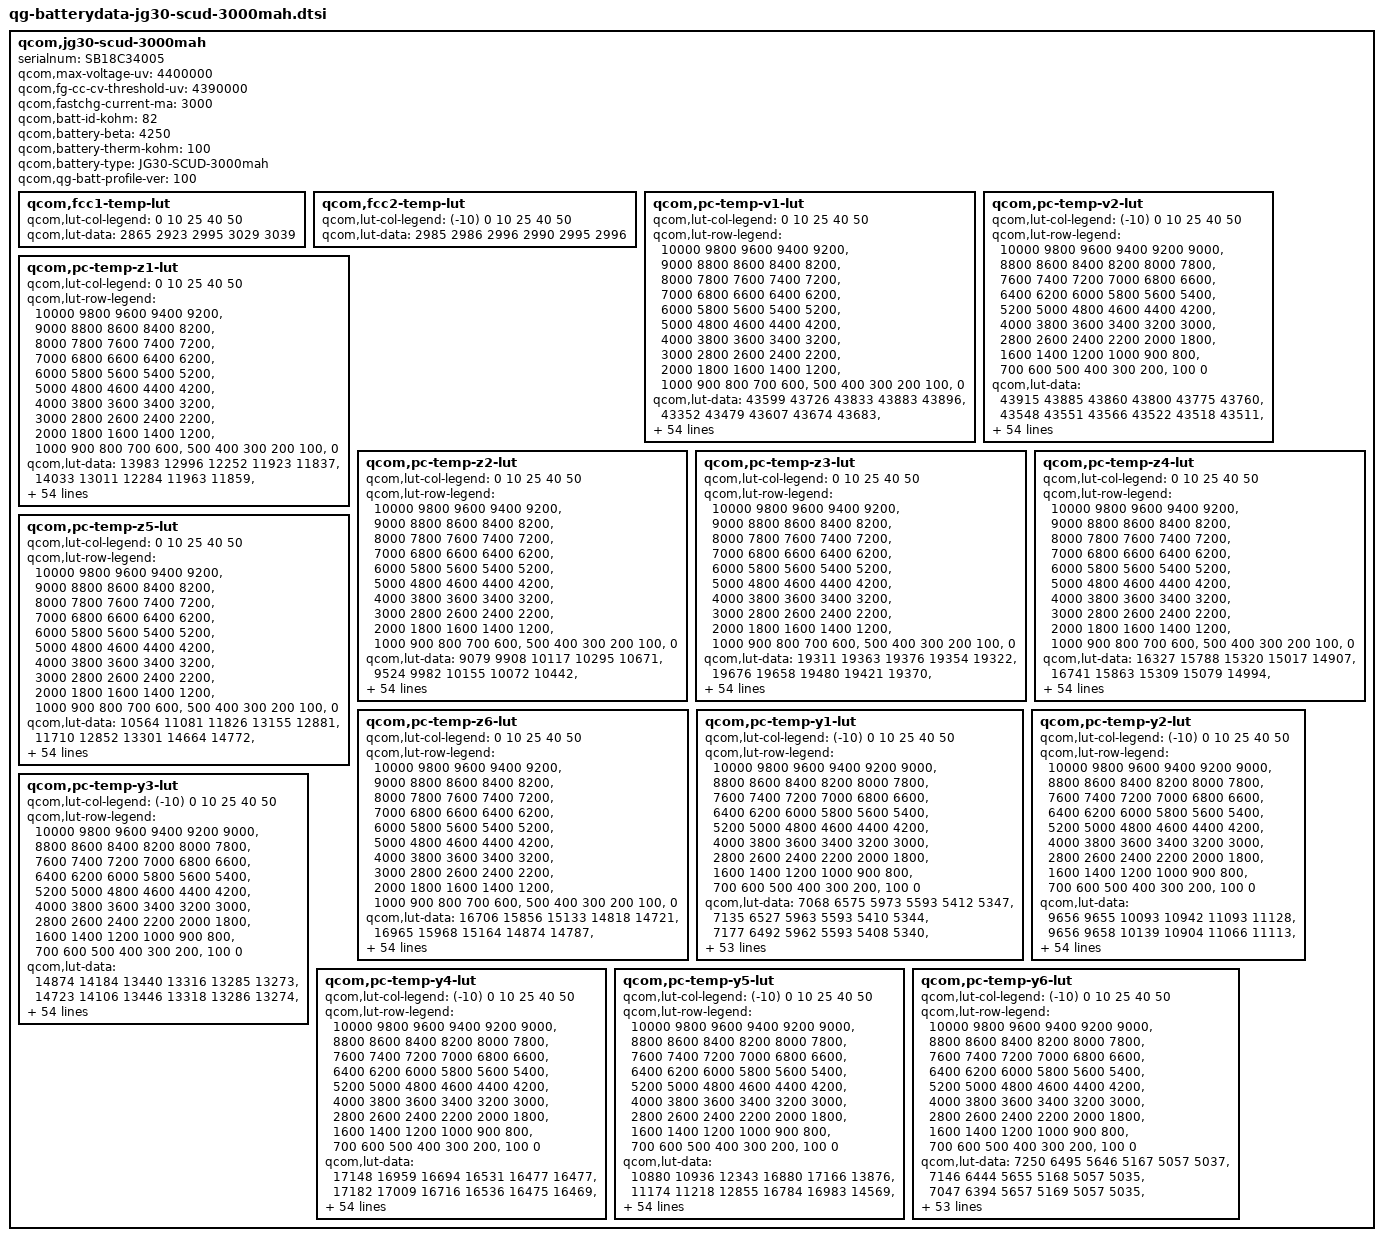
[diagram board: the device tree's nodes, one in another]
/* Copyright (c) 2018, The Linux Foundation. All rights reserved.
 *
 * This program is free software; you can redistribute it and/or modify
 * it under the terms of the GNU General Public License version 2 and
 * only version 2 as published by the Free Software Foundation.
 *
 * This program is distributed in the hope that it will be useful,
 * but WITHOUT ANY WARRANTY; without even the implied warranty of
 * MERCHANTABILITY or FITNESS FOR A PARTICULAR PURPOSE.  See the
 * GNU General Public License for more details.
 */

qcom,jg30-scud-3000mah {
	serialnum = "SB18C34005";
	qcom,max-voltage-uv = <4400000>;
	qcom,fg-cc-cv-threshold-uv = <4390000>;
	qcom,fastchg-current-ma = <3000>;
	qcom,batt-id-kohm = <82>;
	qcom,battery-beta = <4250>;
	qcom,battery-therm-kohm = <100>;
	qcom,battery-type = "JG30-SCUD-3000mah";
	qcom,qg-batt-profile-ver = <100>;

	qcom,fcc1-temp-lut {
		qcom,lut-col-legend = <0 10 25 40 50>;
		qcom,lut-data = <2865 2923 2995 3029 3039>;
	};

	qcom,fcc2-temp-lut {
		qcom,lut-col-legend = <(-10) 0 10 25 40 50>;
		qcom,lut-data = <2985 2986 2996 2990 2995 2996>;
	};

	qcom,pc-temp-v1-lut {
		qcom,lut-col-legend = <0 10 25 40 50>;
		qcom,lut-row-legend = <10000 9800 9600 9400 9200>,
			<9000 8800 8600 8400 8200>,
			<8000 7800 7600 7400 7200>,
			<7000 6800 6600 6400 6200>,
			<6000 5800 5600 5400 5200>,
			<5000 4800 4600 4400 4200>,
			<4000 3800 3600 3400 3200>,
			<3000 2800 2600 2400 2200>,
			<2000 1800 1600 1400 1200>,
			<1000 900 800 700 600>,
			<500 400 300 200 100>,
			<0>;
		qcom,lut-data = <43599 43726 43833 43883 43896>,
			<43352 43479 43607 43674 43683>,
			<43095 43237 43378 43454 43470>,
			<42845 42998 43145 43230 43252>,
			<42612 42763 42909 43000 43025>,
			<42387 42530 42673 42766 42792>,
			<42168 42301 42438 42533 42560>,
			<41955 42078 42205 42297 42329>,
			<41749 41861 41976 42065 42098>,
			<41548 41649 41749 41835 41867>,
			<41353 41444 41527 41607 41637>,
			<41156 41245 41310 41384 41413>,
			<40963 41054 41099 41162 41193>,
			<40762 40876 40901 40950 40979>,
			<40526 40684 40716 40745 40769>,
			<40251 40434 40525 40548 40566>,
			<40021 40158 40308 40355 40371>,
			<39865 39961 40092 40167 40185>,
			<39737 39834 39917 39986 40004>,
			<39609 39719 39776 39823 39835>,
			<39482 39581 39620 39655 39664>,
			<39360 39433 39411 39435 39457>,
			<39237 39266 39182 39169 39211>,
			<39115 39050 38980 38964 39005>,
			<38995 38839 38785 38825 38857>,
			<38873 38693 38641 38711 38731>,
			<38756 38578 38558 38604 38613>,
			<38650 38489 38494 38508 38504>,
			<38548 38423 38428 38417 38406>,
			<38468 38370 38360 38328 38316>,
			<38419 38324 38295 38248 38234>,
			<38380 38285 38230 38177 38161>,
			<38348 38250 38169 38115 38096>,
			<38315 38218 38117 38058 38034>,
			<38281 38189 38074 38006 37978>,
			<38244 38156 38033 37956 37921>,
			<38202 38122 37996 37905 37854>,
			<38152 38081 37957 37853 37781>,
			<38088 38014 37897 37786 37702>,
			<38010 37918 37801 37695 37620>,
			<37911 37809 37690 37589 37528>,
			<37782 37678 37572 37473 37413>,
			<37637 37543 37438 37340 37278>,
			<37477 37411 37274 37178 37116>,
			<37328 37271 37137 37042 36979>,
			<37230 37174 37063 36967 36909>,
			<37194 37144 37039 36952 36892>,
			<37167 37118 37025 36937 36879>,
			<37141 37093 37008 36918 36862>,
			<37086 37042 36954 36857 36789>,
			<36861 36801 36687 36574 36488>,
			<36411 36351 36248 36132 36045>,
			<35837 35774 35670 35553 35469>,
			<35059 34991 34882 34765 34678>,
			<33817 33753 33656 33542 33450>,
			<30000 30000 30000 30000 30000>;
	};

	qcom,pc-temp-v2-lut {
		qcom,lut-col-legend = <(-10) 0 10 25 40 50>;
		qcom,lut-row-legend = <10000 9800 9600 9400 9200 9000>,
			<8800 8600 8400 8200 8000 7800>,
			<7600 7400 7200 7000 6800 6600>,
			<6400 6200 6000 5800 5600 5400>,
			<5200 5000 4800 4600 4400 4200>,
			<4000 3800 3600 3400 3200 3000>,
			<2800 2600 2400 2200 2000 1800>,
			<1600 1400 1200 1000 900 800>,
			<700 600 500 400 300 200>,
			<100 0>;
		qcom,lut-data = <43915 43885 43860 43800 43775 43760>,
			<43548 43551 43566 43522 43518 43511>,
			<43206 43238 43287 43256 43268 43268>,
			<42894 42945 43023 43004 43026 43031>,
			<42608 42673 42776 42765 42792 42800>,
			<42339 42413 42533 42530 42561 42570>,
			<42084 42162 42289 42297 42329 42339>,
			<41842 41921 42049 42066 42098 42108>,
			<41604 41684 41818 41839 41871 41882>,
			<41361 41447 41595 41615 41646 41657>,
			<41161 41235 41378 41395 41423 41436>,
			<41041 41070 41167 41178 41205 41218>,
			<40938 40921 40963 40964 40989 41002>,
			<40727 40733 40774 40763 40783 40794>,
			<40251 40496 40604 40573 40582 40591>,
			<39818 40238 40413 40382 40388 40394>,
			<39603 39948 40154 40174 40199 40205>,
			<39441 39647 39868 39966 40014 40023>,
			<39273 39414 39641 39787 39836 39844>,
			<39102 39233 39456 39639 39667 39673>,
			<38939 39068 39277 39478 39486 39491>,
			<38783 38903 39083 39249 39261 39265>,
			<38635 38746 38893 38994 39023 39029>,
			<38511 38602 38729 38802 38837 38846>,
			<38405 38464 38585 38654 38687 38699>,
			<38312 38345 38456 38528 38558 38571>,
			<38231 38251 38337 38415 38446 38457>,
			<38159 38172 38231 38314 38346 38356>,
			<38091 38102 38139 38223 38254 38262>,
			<38027 38041 38057 38137 38169 38175>,
			<37967 37986 37988 38061 38091 38096>,
			<37909 37935 37929 37990 38020 38024>,
			<37854 37886 37878 37926 37953 37956>,
			<37796 37838 37829 37865 37885 37886>,
			<37737 37793 37785 37811 37815 37814>,
			<37676 37746 37739 37755 37740 37732>,
			<37613 37693 37691 37695 37652 37626>,
			<37548 37635 37639 37632 37556 37508>,
			<37481 37570 37577 37563 37470 37411>,
			<37412 37496 37503 37490 37395 37333>,
			<37344 37414 37419 37407 37313 37249>,
			<37280 37313 37318 37303 37211 37146>,
			<37215 37200 37204 37182 37092 37028>,
			<37143 37099 37082 37037 36942 36874>,
			<37059 37002 36967 36922 36845 36785>,
			<36955 36913 36879 36863 36812 36760>,
			<36891 36874 36836 36852 36800 36750>,
			<36821 36832 36800 36831 36782 36731>,
			<36734 36777 36746 36802 36750 36694>,
			<36604 36678 36648 36729 36649 36565>,
			<36381 36456 36426 36472 36328 36212>,
			<36010 36041 35992 36012 35843 35721>,
			<35441 35429 35393 35403 35207 35069>,
			<34598 34560 34533 34580 34335 34165>,
			<33182 33198 33165 33358 33033 32846>,
			<29031 28864 28947 28781 28877 28872>;
	};

	qcom,pc-temp-z1-lut {
		qcom,lut-col-legend = <0 10 25 40 50>;
		qcom,lut-row-legend = <10000 9800 9600 9400 9200>,
			<9000 8800 8600 8400 8200>,
			<8000 7800 7600 7400 7200>,
			<7000 6800 6600 6400 6200>,
			<6000 5800 5600 5400 5200>,
			<5000 4800 4600 4400 4200>,
			<4000 3800 3600 3400 3200>,
			<3000 2800 2600 2400 2200>,
			<2000 1800 1600 1400 1200>,
			<1000 900 800 700 600>,
			<500 400 300 200 100>,
			<0>;
		qcom,lut-data = <13983 12996 12252 11923 11837>,
			<14033 13011 12284 11963 11859>,
			<14040 13023 12303 11963 11859>,
			<14043 13034 12302 11961 11859>,
			<14021 13038 12289 11956 11856>,
			<13988 13025 12276 11949 11849>,
			<13977 13006 12268 11945 11847>,
			<13974 13000 12263 11942 11846>,
			<13970 12997 12262 11940 11846>,
			<13964 12996 12264 11938 11845>,
			<13956 12997 12265 11936 11844>,
			<13946 12999 12270 11935 11844>,
			<13935 12998 12275 11935 11844>,
			<13920 12989 12273 11934 11844>,
			<13900 12980 12260 11934 11845>,
			<13866 12971 12251 11935 11845>,
			<13840 12963 12254 11936 11846>,
			<13822 12962 12260 11939 11849>,
			<13807 12973 12268 11942 11851>,
			<13803 12985 12281 11945 11853>,
			<13802 12990 12288 11947 11854>,
			<13803 13001 12285 11948 11855>,
			<13818 13010 12280 11950 11856>,
			<13847 13020 12280 11951 11858>,
			<13862 13027 12284 11954 11860>,
			<13859 13024 12289 11957 11864>,
			<13852 13010 12295 11962 11868>,
			<13851 13003 12302 11969 11874>,
			<13854 13016 12305 11974 11879>,
			<13857 13033 12307 11978 11884>,
			<13863 13040 12308 11983 11889>,
			<13869 13048 12311 11987 11893>,
			<13873 13052 12316 11991 11897>,
			<13873 13052 12320 11996 11901>,
			<13873 13054 12324 12004 11904>,
			<13889 13061 12329 12012 11908>,
			<13929 13077 12333 12018 11912>,
			<13950 13090 12339 12023 11917>,
			<13943 13094 12347 12025 11920>,
			<13932 13095 12360 12024 11923>,
			<13936 13099 12369 12024 11925>,
			<13964 13108 12370 12028 11928>,
			<13972 13116 12371 12035 11930>,
			<13961 13130 12369 12037 11933>,
			<13969 13143 12368 12041 11939>,
			<13974 13108 12376 12050 11941>,
			<13952 13109 12377 12048 11945>,
			<13964 13100 12365 12049 11943>,
			<13963 13105 12372 12048 11947>,
			<13981 13103 12375 12051 11950>,
			<14011 13123 12385 12058 11954>,
			<13989 13149 12388 12068 11965>,
			<14050 13179 12410 12082 11975>,
			<14059 13221 12443 12100 11989>,
			<14059 13221 12443 12100 11989>,
			<14059 13221 12443 12100 11989>;
	};

	qcom,pc-temp-z2-lut {
		qcom,lut-col-legend = <0 10 25 40 50>;
		qcom,lut-row-legend = <10000 9800 9600 9400 9200>,
			<9000 8800 8600 8400 8200>,
			<8000 7800 7600 7400 7200>,
			<7000 6800 6600 6400 6200>,
			<6000 5800 5600 5400 5200>,
			<5000 4800 4600 4400 4200>,
			<4000 3800 3600 3400 3200>,
			<3000 2800 2600 2400 2200>,
			<2000 1800 1600 1400 1200>,
			<1000 900 800 700 600>,
			<500 400 300 200 100>,
			<0>;
		qcom,lut-data = <9079 9908 10117 10295 10671>,
			<9524 9982 10155 10072 10442>,
			<9735 9981 10171 10290 10481>,
			<9860 9956 10164 10417 10501>,
			<9877 9931 10118 10382 10489>,
			<9892 9909 10076 10324 10459>,
			<9899 9889 10050 10306 10431>,
			<9902 9875 10031 10300 10399>,
			<9904 9863 10031 10297 10381>,
			<9898 9857 10047 10302 10389>,
			<9884 9854 10063 10311 10403>,
			<9872 9853 10070 10319 10397>,
			<9865 9861 10077 10331 10341>,
			<9858 9900 10091 10335 10302>,
			<9832 9929 10116 10293 10321>,
			<9772 9921 10132 10241 10354>,
			<9738 9904 10136 10245 10370>,
			<9752 9902 10139 10282 10383>,
			<9778 9938 10142 10299 10389>,
			<9793 9971 10148 10280 10391>,
			<9802 9972 10156 10258 10393>,
			<9807 9969 10171 10299 10399>,
			<9805 9965 10186 10434 10428>,
			<9799 9961 10180 10487 10443>,
			<9796 9957 10138 10362 10456>,
			<9798 9956 10108 10230 10476>,
			<9803 9955 10104 10293 10497>,
			<9809 9955 10105 10490 10536>,
			<9821 9960 10122 10557 10548>,
			<9831 9968 10182 10431 10436>,
			<9773 9975 10219 10306 10305>,
			<9655 9982 10199 10295 10273>,
			<9609 9988 10168 10295 10254>,
			<9533 9994 10164 10301 10251>,
			<9467 10001 10170 10333 10281>,
			<9514 10008 10177 10375 10334>,
			<9632 10020 10184 10413 10433>,
			<9710 10031 10195 10456 10576>,
			<9741 10040 10213 10488 10615>,
			<9760 10049 10247 10518 10565>,
			<9753 10057 10267 10534 10514>,
			<9720 10064 10267 10526 10502>,
			<9694 10078 10266 10514 10496>,
			<9669 10145 10280 10519 10486>,
			<9576 11133 10348 10511 10497>,
			<9582 11680 10381 10457 10515>,
			<9567 12478 10367 10453 10508>,
			<9555 12492 10379 10444 10504>,
			<9554 13457 10426 10463 10584>,
			<9508 13973 10441 10548 10637>,
			<9439 11926 10564 10571 10383>,
			<9414 11610 10674 10532 10295>,
			<9337 10774 10701 10396 10418>,
			<9292 10074 10592 10327 10361>,
			<9292 10074 10592 10327 10361>,
			<9292 10074 10592 10327 10361>;
	};

	qcom,pc-temp-z3-lut {
		qcom,lut-col-legend = <0 10 25 40 50>;
		qcom,lut-row-legend = <10000 9800 9600 9400 9200>,
			<9000 8800 8600 8400 8200>,
			<8000 7800 7600 7400 7200>,
			<7000 6800 6600 6400 6200>,
			<6000 5800 5600 5400 5200>,
			<5000 4800 4600 4400 4200>,
			<4000 3800 3600 3400 3200>,
			<3000 2800 2600 2400 2200>,
			<2000 1800 1600 1400 1200>,
			<1000 900 800 700 600>,
			<500 400 300 200 100>,
			<0>;
		qcom,lut-data = <19311 19363 19376 19354 19322>,
			<19676 19658 19480 19421 19370>,
			<19932 19752 19553 19444 19390>,
			<20048 19800 19578 19456 19407>,
			<20039 19820 19590 19464 19421>,
			<20021 19829 19595 19469 19432>,
			<19997 19835 19595 19469 19433>,
			<19955 19834 19593 19461 19419>,
			<19924 19829 19587 19452 19406>,
			<19922 19823 19571 19441 19401>,
			<19928 19816 19558 19430 19398>,
			<19926 19806 19552 19424 19391>,
			<19903 19784 19545 19420 19377>,
			<19879 19718 19533 19415 19367>,
			<19909 19671 19507 19399 19363>,
			<20029 19687 19492 19383 19361>,
			<20103 19721 19493 19382 19356>,
			<20069 19728 19494 19384 19349>,
			<20007 19691 19494 19384 19346>,
			<19971 19655 19491 19383 19347>,
			<19949 19659 19489 19382 19350>,
			<19937 19678 19502 19388 19354>,
			<19943 19698 19522 19408 19362>,
			<19960 19721 19525 19415 19365>,
			<19974 19740 19519 19391 19347>,
			<19986 19741 19510 19365 19325>,
			<19995 19739 19495 19368 19339>,
			<19996 19736 19478 19383 19394>,
			<19992 19731 19476 19399 19419>,
			<19985 19726 19481 19422 19412>,
			<19880 19719 19487 19440 19401>,
			<19682 19709 19505 19437 19392>,
			<19593 19699 19529 19426 19381>,
			<19436 19687 19532 19416 19372>,
			<19285 19675 19523 19408 19366>,
			<19270 19664 19513 19403 19363>,
			<19267 19654 19506 19401 19364>,
			<19265 19648 19500 19400 19369>,
			<19264 19648 19495 19398 19370>,
			<19264 19648 19491 19397 19366>,
			<19264 19648 19488 19395 19361>,
			<19264 19645 19484 19390 19355>,
			<19264 19620 19480 19385 19350>,
			<19265 19309 19476 19386 19353>,
			<19266 19259 19462 19380 19353>,
			<19266 19258 19431 19370 19343>,
			<19266 19257 19431 19357 19339>,
			<19267 19257 19406 19354 19336>,
			<19267 19257 19375 19354 19323>,
			<19268 19257 19382 19344 19326>,
			<19270 19258 19372 19342 19355>,
			<19271 19258 19339 19342 19359>,
			<19275 19259 19326 19356 19330>,
			<19278 19262 19325 19361 19335>,
			<19278 19262 19325 19361 19335>,
			<19278 19262 19325 19361 19335>;
	};

	qcom,pc-temp-z4-lut {
		qcom,lut-col-legend = <0 10 25 40 50>;
		qcom,lut-row-legend = <10000 9800 9600 9400 9200>,
			<9000 8800 8600 8400 8200>,
			<8000 7800 7600 7400 7200>,
			<7000 6800 6600 6400 6200>,
			<6000 5800 5600 5400 5200>,
			<5000 4800 4600 4400 4200>,
			<4000 3800 3600 3400 3200>,
			<3000 2800 2600 2400 2200>,
			<2000 1800 1600 1400 1200>,
			<1000 900 800 700 600>,
			<500 400 300 200 100>,
			<0>;
		qcom,lut-data = <16327 15788 15320 15017 14907>,
			<16741 15863 15309 15079 14994>,
			<16534 15799 15282 15047 14967>,
			<16321 15580 15234 15005 14930>,
			<16135 15391 15131 14960 14892>,
			<15958 15267 15035 14910 14851>,
			<15826 15164 14972 14869 14823>,
			<15726 15084 14920 14832 14803>,
			<15637 15018 14878 14808 14787>,
			<15546 14966 14842 14796 14774>,
			<15458 14922 14818 14788 14762>,
			<15393 14889 14807 14775 14755>,
			<15353 14880 14798 14760 14752>,
			<15314 14878 14787 14750 14747>,
			<15241 14875 14771 14746 14736>,
			<15123 14863 14760 14743 14722>,
			<15043 14842 14754 14734 14712>,
			<15018 14829 14750 14717 14705>,
			<15002 14823 14741 14707 14699>,
			<14986 14816 14726 14703 14694>,
			<14969 14800 14718 14700 14689>,
			<14950 14773 14746 14726 14707>,
			<14923 14765 14801 14812 14784>,
			<14889 14819 14856 14871 14846>,
			<14869 14885 14924 14903 14878>,
			<14861 14904 14958 14921 14897>,
			<14856 14915 14948 14910 14875>,
			<14856 14918 14926 14869 14794>,
			<14861 14903 14901 14827 14743>,
			<14866 14875 14868 14777 14728>,
			<14963 14852 14834 14737 14718>,
			<15147 14831 14794 14722 14708>,
			<15219 14813 14757 14712 14699>,
			<15363 14800 14746 14710 14697>,
			<15501 14788 14742 14711 14698>,
			<15499 14777 14739 14712 14701>,
			<15474 14766 14738 14717 14712>,
			<15449 14760 14737 14726 14735>,
			<15427 14759 14741 14735 14742>,
			<15407 14759 14760 14747 14742>,
			<15389 14758 14772 14754 14741>,
			<15376 14754 14763 14749 14736>,
			<15356 14769 14754 14741 14730>,
			<15317 15076 14754 14742 14732>,
			<15164 15050 14737 14735 14725>,
			<15135 15015 14717 14709 14702>,
			<15126 15004 14700 14699 14685>,
			<15120 14994 14708 14675 14662>,
			<15112 14985 14727 14656 14654>,
			<15102 14981 14719 14678 14668>,
			<15099 14996 14767 14716 14665>,
			<15127 15011 14814 14719 14663>,
			<15149 15023 14830 14706 14695>,
			<15175 15039 14838 14701 14691>,
			<15175 15039 14838 14701 14691>,
			<15175 15039 14838 14701 14691>;
	};

	qcom,pc-temp-z5-lut {
		qcom,lut-col-legend = <0 10 25 40 50>;
		qcom,lut-row-legend = <10000 9800 9600 9400 9200>,
			<9000 8800 8600 8400 8200>,
			<8000 7800 7600 7400 7200>,
			<7000 6800 6600 6400 6200>,
			<6000 5800 5600 5400 5200>,
			<5000 4800 4600 4400 4200>,
			<4000 3800 3600 3400 3200>,
			<3000 2800 2600 2400 2200>,
			<2000 1800 1600 1400 1200>,
			<1000 900 800 700 600>,
			<500 400 300 200 100>,
			<0>;
		qcom,lut-data = <10564 11081 11826 13155 12881>,
			<11710 12852 13301 14664 14772>,
			<12486 13688 14408 15327 15305>,
			<12860 14195 14993 15710 15815>,
			<12937 14627 15341 15964 16499>,
			<12979 15044 15668 16164 17190>,
			<12977 15440 16105 16464 17322>,
			<12924 15856 16560 16951 17042>,
			<12880 16305 17004 17193 16826>,
			<12973 16735 17711 17083 17001>,
			<13185 17339 18179 16924 17324>,
			<13256 17945 18482 17033 17294>,
			<12997 17812 18805 17570 16633>,
			<12705 16149 18729 17842 16176>,
			<13377 14866 18170 17216 16512>,
			<16031 16508 17832 16438 17086>,
			<17648 19813 18301 16649 17294>,
			<17097 20687 19304 17888 17355>,
			<16172 18905 20380 19116 17470>,
			<15872 17239 21698 19930 18825>,
			<15885 18235 23731 20917 20835>,
			<15993 21937 30821 23781 21843>,
			<16648 26625 39420 29217 22584>,
			<18423 35029 39889 31094 22802>,
			<20515 42398 34247 24346 19054>,
			<23351 42172 28337 16951 14442>,
			<26292 38342 23628 15864 14658>,
			<28150 34832 19773 15469 17195>,
			<29630 32608 18585 15516 18994>,
			<30341 30724 18100 18036 20067>,
			<27452 29127 18005 21362 20881>,
			<21612 27723 21402 23463 21402>,
			<18679 26429 27055 25213 22322>,
			<14624 25011 29796 26699 23291>,
			<10977 23749 31436 28245 24994>,
			<10680 23309 32115 29170 26319>,
			<10671 23153 31750 28963 26314>,
			<10667 23081 30971 28236 26069>,
			<10675 24223 29883 27123 25462>,
			<10692 26840 27500 24182 22540>,
			<10709 27793 25531 21461 19572>,
			<10729 27638 24762 20401 18412>,
			<10757 26497 24091 19662 17674>,
			<10804 12945 22846 18882 17077>,
			<11062 11114 22961 18486 17306>,
			<11041 11103 20556 18948 17174>,
			<11030 11045 21012 17593 17603>,
			<11020 11043 18178 18874 19581>,
			<11019 11031 14663 21248 18799>,
			<11041 11065 15411 17305 16909>,
			<11108 11138 13980 14228 17811>,
			<11062 11085 12421 13784 17968>,
			<10991 11026 12017 14498 13903>,
			<10909 10960 11852 14617 14022>,
			<10909 10960 11852 14617 14022>,
			<10909 10960 11852 14617 14022>;
	};

	qcom,pc-temp-z6-lut {
		qcom,lut-col-legend = <0 10 25 40 50>;
		qcom,lut-row-legend = <10000 9800 9600 9400 9200>,
			<9000 8800 8600 8400 8200>,
			<8000 7800 7600 7400 7200>,
			<7000 6800 6600 6400 6200>,
			<6000 5800 5600 5400 5200>,
			<5000 4800 4600 4400 4200>,
			<4000 3800 3600 3400 3200>,
			<3000 2800 2600 2400 2200>,
			<2000 1800 1600 1400 1200>,
			<1000 900 800 700 600>,
			<500 400 300 200 100>,
			<0>;
		qcom,lut-data = <16706 15856 15133 14818 14721>,
			<16965 15968 15164 14874 14787>,
			<16899 15941 15173 14871 14785>,
			<16816 15823 15163 14866 14781>,
			<16689 15714 15112 14851 14774>,
			<16535 15634 15060 14828 14761>,
			<16416 15564 15026 14808 14748>,
			<16317 15506 14995 14787 14732>,
			<16234 15456 14968 14770 14718>,
			<16169 15414 14941 14759 14709>,
			<16115 15384 14923 14749 14702>,
			<16061 15357 14915 14740 14694>,
			<16000 15322 14909 14731 14686>,
			<15948 15274 14895 14723 14677>,
			<15924 15245 14870 14713 14670>,
			<15911 15245 14854 14703 14663>,
			<15895 15246 14853 14696 14656>,
			<15857 15244 14852 14691 14649>,
			<15810 15226 14850 14687 14645>,
			<15783 15210 14844 14685 14644>,
			<15766 15209 14841 14684 14644>,
			<15756 15213 14860 14700 14654>,
			<15754 15220 14895 14752 14695>,
			<15753 15257 14923 14774 14719>,
			<15753 15299 14949 14774 14722>,
			<15758 15311 14962 14774 14724>,
			<15766 15318 14953 14771 14722>,
			<15770 15320 14938 14764 14717>,
			<15773 15313 14926 14756 14710>,
			<15775 15302 14917 14749 14701>,
			<15767 15292 14910 14742 14692>,
			<15750 15282 14907 14733 14683>,
			<15738 15273 14905 14725 14674>,
			<15726 15265 14902 14720 14669>,
			<15714 15259 14898 14717 14666>,
			<15708 15255 14895 14715 14665>,
			<15703 15252 14894 14717 14671>,
			<15701 15251 14893 14721 14684>,
			<15702 15254 14895 14725 14688>,
			<15703 15261 14904 14730 14686>,
			<15704 15268 14910 14733 14683>,
			<15707 15272 14908 14729 14679>,
			<15708 15273 14905 14725 14675>,
			<15702 15263 14908 14727 14678>,
			<15653 15236 14900 14722 14676>,
			<15643 15226 14879 14707 14661>,
			<15640 15223 14873 14696 14652>,
			<15639 15222 14864 14685 14640>,
			<15639 15219 14859 14677 14630>,
			<15644 15224 14863 14682 14638>,
			<15658 15240 14883 14700 14654>,
			<15682 15258 14892 14704 14658>,
			<15718 15278 14899 14709 14660>,
			<15762 15310 14913 14715 14664>,
			<15762 15310 14913 14715 14664>,
			<15762 15310 14913 14715 14664>;
	};

	qcom,pc-temp-y1-lut {
		qcom,lut-col-legend = <(-10) 0 10 25 40 50>;
		qcom,lut-row-legend = <10000 9800 9600 9400 9200 9000>,
			<8800 8600 8400 8200 8000 7800>,
			<7600 7400 7200 7000 6800 6600>,
			<6400 6200 6000 5800 5600 5400>,
			<5200 5000 4800 4600 4400 4200>,
			<4000 3800 3600 3400 3200 3000>,
			<2800 2600 2400 2200 2000 1800>,
			<1600 1400 1200 1000 900 800>,
			<700 600 500 400 300 200>,
			<100 0>;
		qcom,lut-data = <7068 6575 5973 5593 5412 5347>,
			<7135 6527 5963 5593 5410 5344>,
			<7177 6492 5962 5593 5408 5340>,
			<7202 6467 5966 5593 5406 5337>,
			<7213 6453 5971 5592 5405 5334>,
			<7216 6448 5974 5592 5404 5332>,
			<7199 6459 5980 5592 5402 5330>,
			<7172 6477 5988 5592 5401 5329>,
			<7172 6478 5989 5591 5400 5327>,
			<7207 6462 5989 5587 5396 5326>,
			<7232 6450 5988 5584 5394 5325>,
			<7219 6450 5981 5582 5393 5324>,
			<7195 6451 5970 5580 5392 5324>,
			<7192 6451 5968 5580 5391 5323>,
			<7207 6448 5970 5582 5388 5322>,
			<7219 6447 5973 5584 5387 5321>,
			<7217 6458 5982 5586 5387 5322>,
			<7211 6477 5993 5587 5388 5322>,
			<7213 6481 5996 5589 5388 5322>,
			<7239 6475 5993 5590 5389 5322>,
			<7259 6470 5991 5591 5389 5322>,
			<7247 6473 5993 5591 5390 5323>,
			<7223 6477 5995 5590 5391 5325>,
			<7218 6478 5996 5592 5393 5326>,
			<7227 6478 5996 5595 5395 5327>,
			<7237 6478 5996 5598 5397 5328>,
			<7239 6478 5996 5601 5399 5330>,
			<7236 6478 5995 5604 5401 5331>,
			<7233 6477 5994 5606 5403 5334>,
			<7224 6471 5991 5609 5405 5337>,
			<7216 6466 5990 5612 5407 5340>,
			<7222 6466 5990 5613 5410 5342>,
			<7245 6468 5991 5615 5414 5344>,
			<7248 6470 5991 5618 5418 5346>,
			<7220 6477 5989 5626 5421 5348>,
			<7196 6483 5989 5633 5425 5351>,
			<7194 6481 5996 5634 5427 5353>,
			<7195 6478 6008 5632 5429 5355>,
			<7198 6478 6011 5630 5430 5356>,
			<7225 6478 6011 5624 5432 5358>,
			<7250 6479 6010 5620 5433 5360>,
			<7238 6483 6010 5621 5434 5362>,
			<7211 6491 6009 5624 5436 5365>,
			<7222 6482 6003 5627 5440 5368>,
			<7238 6477 6002 5634 5444 5372>,
			<7270 6513 6035 5645 5443 5374>,
			<7275 6511 6047 5647 5453 5376>,
			<7291 6530 6033 5644 5450 5377>,
			<7352 6541 6033 5649 5450 5378>,
			<7370 6557 6041 5642 5450 5377>,
			<7334 6559 6053 5653 5454 5382>,
			<7359 6572 6064 5652 5458 5388>,
			<7454 6605 6070 5673 5471 5394>,
			<7525 6652 6116 5698 5481 5403>,
			<7525 6652 6116 5698 5481 5403>,
			<7525 6652 6116 5698 5481 5403>;
	};

	qcom,pc-temp-y2-lut {
		qcom,lut-col-legend = <(-10) 0 10 25 40 50>;
		qcom,lut-row-legend = <10000 9800 9600 9400 9200 9000>,
			<8800 8600 8400 8200 8000 7800>,
			<7600 7400 7200 7000 6800 6600>,
			<6400 6200 6000 5800 5600 5400>,
			<5200 5000 4800 4600 4400 4200>,
			<4000 3800 3600 3400 3200 3000>,
			<2800 2600 2400 2200 2000 1800>,
			<1600 1400 1200 1000 900 800>,
			<700 600 500 400 300 200>,
			<100 0>;
		qcom,lut-data = <9656 9655 10093 10942 11093 11128>,
			<9656 9658 10139 10904 11066 11113>,
			<9656 9661 10185 10862 11039 11094>,
			<9657 9664 10228 10821 11012 11073>,
			<9657 9667 10266 10787 10987 11050>,
			<9658 9669 10296 10763 10964 11024>,
			<9658 9672 10321 10747 10939 10987>,
			<9659 9675 10341 10735 10919 10954>,
			<9659 9678 10344 10731 10917 10955>,
			<9659 9683 10342 10732 10927 10994>,
			<9659 9686 10341 10733 10936 11027>,
			<9660 9686 10404 10736 10943 11038>,
			<9661 9685 10511 10744 10954 11047>,
			<9661 9686 10555 10759 10966 11057>,
			<9660 9689 10573 10800 10988 11068>,
			<9660 9692 10588 10841 11017 11083>,
			<9660 9685 10602 10863 11056 11116>,
			<9660 9674 10615 10882 11109 11168>,
			<9660 9671 10631 10913 11168 11234>,
			<9660 9671 10654 10965 11249 11334>,
			<9660 9671 10672 10996 11293 11390>,
			<9660 9670 10682 10972 11249 11304>,
			<9660 9669 10690 10930 11164 11164>,
			<9660 9669 10695 10921 11112 11138>,
			<9659 9668 10700 10933 11072 11161>,
			<9659 9668 10703 10948 11054 11186>,
			<9659 9667 10699 10961 11078 11206>,
			<9659 9667 10685 10974 11130 11230>,
			<9659 9666 10580 10982 11180 11254>,
			<9659 9665 10089 10987 11249 11277>,
			<9659 9665 9754 10991 11293 11307>,
			<9659 9664 9887 10997 11301 11377>,
			<9658 9663 10122 11003 11305 11465>,
			<9658 9662 10133 11005 11310 11494>,
			<9658 9661 9886 11005 11313 11499>,
			<9658 9660 9703 11003 11309 11493>,
			<9658 9660 9691 10988 11272 11415>,
			<9658 9659 9685 10962 11209 11288>,
			<9657 9659 9680 10942 11172 11237>,
			<9657 9658 9676 10928 11141 11216>,
			<9657 9658 9673 10910 11125 11203>,
			<9657 9657 9669 10882 11139 11205>,
			<9657 9657 9666 10843 11155 11212>,
			<9657 9656 9664 10786 11124 11260>,
			<9656 9656 9662 10720 11030 11213>,
			<9656 9656 9663 10701 10997 10992>,
			<9656 9656 9662 10687 11006 11016>,
			<9656 9656 9661 10682 11007 10975>,
			<9656 9656 9660 10685 10966 10954>,
			<9655 9655 9660 10683 10953 10900>,
			<9655 9655 9659 10643 10942 10929>,
			<9654 9655 9658 10580 10881 10911>,
			<9653 9655 9656 10513 10854 10844>,
			<9651 9653 9655 10455 10788 10779>,
			<9651 9653 9655 10455 10788 10779>,
			<9651 9653 9655 10455 10788 10779>;
	};

	qcom,pc-temp-y3-lut {
		qcom,lut-col-legend = <(-10) 0 10 25 40 50>;
		qcom,lut-row-legend = <10000 9800 9600 9400 9200 9000>,
			<8800 8600 8400 8200 8000 7800>,
			<7600 7400 7200 7000 6800 6600>,
			<6400 6200 6000 5800 5600 5400>,
			<5200 5000 4800 4600 4400 4200>,
			<4000 3800 3600 3400 3200 3000>,
			<2800 2600 2400 2200 2000 1800>,
			<1600 1400 1200 1000 900 800>,
			<700 600 500 400 300 200>,
			<100 0>;
		qcom,lut-data = <14874 14184 13440 13316 13285 13273>,
			<14723 14106 13446 13318 13286 13274>,
			<14575 14032 13451 13320 13287 13276>,
			<14438 13963 13457 13322 13288 13278>,
			<14318 13901 13460 13323 13289 13279>,
			<14223 13848 13462 13325 13291 13280>,
			<14156 13804 13461 13327 13292 13281>,
			<14099 13766 13459 13329 13294 13282>,
			<14031 13731 13459 13331 13295 13285>,
			<13942 13701 13457 13332 13296 13289>,
			<13893 13669 13455 13333 13297 13293>,
			<13893 13624 13449 13334 13297 13294>,
			<13894 13581 13440 13335 13297 13295>,
			<13884 13575 13433 13335 13298 13295>,
			<13822 13595 13425 13336 13303 13294>,
			<13773 13609 13418 13335 13305 13294>,
			<13766 13582 13413 13332 13305 13295>,
			<13763 13530 13409 13327 13305 13297>,
			<13761 13504 13404 13327 13305 13297>,
			<13761 13491 13398 13331 13304 13296>,
			<13760 13481 13391 13334 13301 13294>,
			<13760 13475 13384 13329 13297 13289>,
			<13759 13469 13376 13321 13292 13282>,
			<13759 13464 13369 13316 13289 13280>,
			<13768 13456 13363 13312 13287 13280>,
			<13780 13451 13359 13311 13286 13280>,
			<13794 13452 13358 13310 13286 13280>,
			<13813 13454 13358 13310 13285 13280>,
			<13833 13458 13350 13310 13286 13280>,
			<13856 13469 13307 13311 13287 13280>,
			<13882 13486 13278 13312 13288 13280>,
			<13916 13508 13303 13312 13289 13281>,
			<13956 13537 13346 13313 13290 13281>,
			<13992 13569 13359 13314 13290 13282>,
			<14024 13603 13363 13315 13290 13283>,
			<14059 13639 13366 13315 13290 13283>,
			<14103 13675 13372 13315 13289 13282>,
			<14154 13713 13380 13314 13286 13280>,
			<14206 13756 13390 13314 13285 13279>,
			<14256 13804 13405 13313 13285 13279>,
			<14311 13856 13424 13313 13284 13280>,
			<14375 13907 13449 13313 13285 13281>,
			<14447 13961 13480 13314 13285 13283>,
			<14521 14027 13519 13314 13285 13278>,
			<14597 14096 13570 13315 13286 13277>,
			<14582 14088 13559 13315 13290 13284>,
			<14580 14096 13576 13322 13292 13290>,
			<14670 14158 13622 13324 13295 13290>,
			<14752 14216 13657 13333 13303 13295>,
			<14835 14271 13684 13344 13304 13292>,
			<14924 14323 13710 13337 13296 13286>,
			<15138 14409 13761 13339 13299 13293>,
			<15637 14529 13885 13347 13304 13294>,
			<16519 14812 14061 13360 13309 13296>,
			<16519 14812 14061 13360 13309 13296>,
			<16519 14812 14061 13360 13309 13296>;
	};

	qcom,pc-temp-y4-lut {
		qcom,lut-col-legend = <(-10) 0 10 25 40 50>;
		qcom,lut-row-legend = <10000 9800 9600 9400 9200 9000>,
			<8800 8600 8400 8200 8000 7800>,
			<7600 7400 7200 7000 6800 6600>,
			<6400 6200 6000 5800 5600 5400>,
			<5200 5000 4800 4600 4400 4200>,
			<4000 3800 3600 3400 3200 3000>,
			<2800 2600 2400 2200 2000 1800>,
			<1600 1400 1200 1000 900 800>,
			<700 600 500 400 300 200>,
			<100 0>;
		qcom,lut-data = <17148 16959 16694 16531 16477 16477>,
			<17182 17009 16716 16536 16475 16469>,
			<17231 17069 16755 16541 16474 16465>,
			<17281 17126 16798 16545 16474 16462>,
			<17321 17170 16833 16549 16475 16461>,
			<17337 17188 16848 16552 16475 16460>,
			<17333 17180 16846 16554 16477 16463>,
			<17325 17166 16843 16556 16480 16467>,
			<17331 17160 16844 16559 16484 16468>,
			<17385 17156 16854 16565 16489 16466>,
			<17449 17155 16870 16572 16495 16466>,
			<17513 17241 16898 16580 16504 16470>,
			<17571 17388 16941 16591 16515 16478>,
			<17539 17402 16990 16607 16524 16488>,
			<17254 17269 17057 16637 16531 16500>,
			<17041 17124 17094 16667 16540 16512>,
			<17034 17027 17011 16695 16556 16523>,
			<17032 16947 16870 16719 16577 16535>,
			<17023 16911 16815 16731 16599 16552>,
			<16993 16896 16796 16739 16628 16577>,
			<16961 16881 16775 16742 16643 16591>,
			<16937 16850 16728 16681 16601 16562>,
			<16918 16811 16671 16570 16528 16509>,
			<16909 16784 16641 16531 16497 16485>,
			<16905 16761 16625 16519 16483 16471>,
			<16903 16750 16610 16514 16477 16466>,
			<16900 16753 16588 16516 16481 16469>,
			<16898 16761 16567 16522 16491 16477>,
			<16898 16767 16578 16529 16501 16487>,
			<16901 16773 16657 16537 16513 16499>,
			<16903 16776 16711 16545 16526 16512>,
			<16900 16774 16679 16554 16541 16528>,
			<16894 16770 16627 16562 16554 16543>,
			<16892 16769 16621 16566 16557 16546>,
			<16896 16772 16653 16568 16554 16545>,
			<16902 16776 16686 16569 16550 16543>,
			<16906 16784 16703 16564 16531 16521>,
			<16911 16795 16716 16553 16503 16487>,
			<16921 16800 16725 16550 16497 16480>,
			<16942 16802 16734 16550 16498 16479>,
			<16968 16803 16737 16550 16498 16479>,
			<16992 16795 16733 16551 16497 16475>,
			<17019 16783 16727 16553 16494 16469>,
			<17064 16783 16726 16547 16483 16464>,
			<17086 16790 16732 16542 16476 16464>,
			<17013 16792 16719 16542 16481 16469>,
			<16974 16794 16741 16552 16494 16473>,
			<16994 16823 16781 16579 16510 16487>,
			<17015 16862 16829 16608 16519 16501>,
			<17023 16902 16874 16633 16521 16499>,
			<17013 16896 16873 16594 16486 16466>,
			<17037 16851 16830 16573 16479 16461>,
			<17186 16842 16868 16585 16490 16470>,
			<17547 16914 16861 16623 16528 16508>,
			<17547 16914 16861 16623 16528 16508>,
			<17547 16914 16861 16623 16528 16508>;
	};

	qcom,pc-temp-y5-lut {
		qcom,lut-col-legend = <(-10) 0 10 25 40 50>;
		qcom,lut-row-legend = <10000 9800 9600 9400 9200 9000>,
			<8800 8600 8400 8200 8000 7800>,
			<7600 7400 7200 7000 6800 6600>,
			<6400 6200 6000 5800 5600 5400>,
			<5200 5000 4800 4600 4400 4200>,
			<4000 3800 3600 3400 3200 3000>,
			<2800 2600 2400 2200 2000 1800>,
			<1600 1400 1200 1000 900 800>,
			<700 600 500 400 300 200>,
			<100 0>;
		qcom,lut-data = <10880 10936 12343 16880 17166 13876>,
			<11174 11218 12855 16784 16983 14569>,
			<11481 11526 13396 16655 16740 15014>,
			<11776 11824 13912 16504 16467 15265>,
			<12032 12078 14348 16342 16194 15376>,
			<12223 12252 14649 16179 15954 15401>,
			<12376 12368 14839 16023 15741 15165>,
			<12492 12451 14976 15844 15509 14797>,
			<12446 12466 15055 15582 15229 14947>,
			<12054 12430 15079 15164 14886 16145>,
			<11779 12409 15005 14771 14502 16935>,
			<13471 12502 14343 14433 13966 16539>,
			<16362 12758 13424 14104 13458 15724>,
			<16650 13706 13597 13856 13398 14968>,
			<14213 17593 15605 13486 13582 14117>,
			<12424 20325 17348 13267 13705 13666>,
			<12421 18051 18006 13311 13541 13644>,
			<12450 13976 18488 13446 13275 13633>,
			<12476 12942 18942 14058 13286 13648>,
			<12524 12983 19463 16868 13768 13767>,
			<12551 13033 19726 19119 14518 13973>,
			<12350 13048 19632 19603 16241 14786>,
			<11949 13067 19410 19882 18330 16001>,
			<11735 12987 19088 19746 18607 16597>,
			<11617 12510 18489 18492 17673 16985>,
			<11561 12011 18135 17400 16721 17160>,
			<11568 11732 18528 17093 16046 16628>,
			<11582 11518 19172 16896 15450 15686>,
			<11584 11432 18561 16918 15305 15247>,
			<11569 11392 14345 17129 15405 15009>,
			<11556 11374 11471 17421 15583 14909>,
			<11653 11453 12312 17906 15958 14973>,
			<11852 11664 13728 18567 16517 15146>,
			<11909 11900 13924 18993 16937 15514>,
			<11884 12223 13212 19310 17309 16508>,
			<11850 12476 12690 19470 17497 17142>,
			<11821 12555 12758 19187 17241 17025>,
			<11788 12602 12891 18481 16661 16749>,
			<11730 12680 12917 17775 16074 16421>,
			<11581 12840 12923 16988 15364 15932>,
			<11466 12955 12932 16283 14870 15652>,
			<11565 12770 12899 15739 14691 16091>,
			<11774 12456 12851 15308 14610 16583>,
			<11922 12431 12711 15153 15330 15713>,
			<12106 12385 12558 15191 15868 15055>,
			<12412 12195 12731 14559 15481 15546>,
			<12495 12354 12455 14973 14570 16174>,
			<12662 12570 12779 14178 14017 15018>,
			<12874 12796 12993 14550 15133 16075>,
			<13050 13022 13335 15826 16025 15453>,
			<13026 12859 13461 15549 16029 15510>,
			<12499 12643 12911 16270 17810 21227>,
			<11410 12433 12553 16990 19827 21466>,
			<10508 11810 12580 17937 21690 22053>,
			<10508 11810 12580 17937 21690 22053>,
			<10508 11810 12580 17937 21690 22053>;
	};

	qcom,pc-temp-y6-lut {
		qcom,lut-col-legend = <(-10) 0 10 25 40 50>;
		qcom,lut-row-legend = <10000 9800 9600 9400 9200 9000>,
			<8800 8600 8400 8200 8000 7800>,
			<7600 7400 7200 7000 6800 6600>,
			<6400 6200 6000 5800 5600 5400>,
			<5200 5000 4800 4600 4400 4200>,
			<4000 3800 3600 3400 3200 3000>,
			<2800 2600 2400 2200 2000 1800>,
			<1600 1400 1200 1000 900 800>,
			<700 600 500 400 300 200>,
			<100 0>;
		qcom,lut-data = <7250 6495 5646 5167 5057 5037>,
			<7146 6444 5655 5168 5057 5035>,
			<7047 6394 5657 5169 5057 5035>,
			<6955 6347 5655 5169 5058 5035>,
			<6873 6301 5650 5169 5058 5035>,
			<6804 6258 5642 5169 5059 5036>,
			<6747 6216 5631 5169 5060 5037>,
			<6699 6177 5616 5168 5062 5039>,
			<6652 6140 5605 5168 5063 5041>,
			<6602 6102 5596 5169 5065 5043>,
			<6577 6080 5589 5169 5067 5045>,
			<6583 6076 5583 5171 5070 5048>,
			<6595 6074 5579 5173 5072 5050>,
			<6580 6066 5580 5177 5076 5053>,
			<6466 6040 5589 5184 5080 5056>,
			<6378 6007 5595 5191 5085 5059>,
			<6372 5962 5572 5197 5090 5063>,
			<6370 5913 5531 5202 5095 5068>,
			<6365 5891 5511 5206 5101 5073>,
			<6358 5882 5501 5210 5107 5078>,
			<6350 5874 5491 5212 5110 5081>,
			<6344 5865 5473 5191 5096 5069>,
			<6338 5856 5454 5154 5071 5049>,
			<6337 5851 5446 5140 5060 5040>,
			<6344 5848 5441 5136 5054 5036>,
			<6354 5846 5439 5134 5052 5035>,
			<6364 5851 5440 5135 5053 5036>,
			<6377 5863 5443 5138 5056 5039>,
			<6392 5876 5447 5142 5059 5041>,
			<6411 5892 5454 5146 5064 5045>,
			<6432 5911 5463 5152 5069 5050>,
			<6455 5932 5475 5157 5075 5055>,
			<6482 5955 5492 5161 5080 5060>,
			<6510 5981 5510 5166 5081 5061>,
			<6538 6011 5531 5170 5081 5061>,
			<6568 6043 5555 5172 5080 5062>,
			<6602 6076 5581 5172 5074 5055>,
			<6640 6111 5611 5172 5065 5044>,
			<6682 6149 5642 5173 5063 5041>,
			<6727 6192 5676 5176 5063 5042>,
			<6778 6236 5712 5181 5064 5042>,
			<6836 6276 5749 5186 5064 5042>,
			<6902 6317 5791 5193 5064 5042>,
			<6975 6368 5842 5199 5062 5038>,
			<7048 6428 5902 5207 5061 5038>,
			<7029 6431 5885 5209 5066 5045>,
			<7027 6440 5909 5218 5072 5050>,
			<7102 6496 5962 5232 5079 5055>,
			<7174 6553 6006 5253 5088 5062>,
			<7248 6612 6043 5272 5090 5060>,
			<7319 6655 6068 5259 5074 5046>,
			<7520 6714 6110 5266 5076 5050>,
			<8014 6810 6236 5294 5084 5055>,
			<8864 7084 6389 5337 5101 5069>,
			<8864 7084 6389 5337 5101 5069>,
			<8864 7084 6389 5337 5101 5069>;
	};

};
